# FM33A0XXEV register map
File version: 1.0
CPU: SC000, little endian, no MPU, no FPU, 3 interrupt priority bits
Registers are 32-bit, read-write, reset 0x0 unless marked. A register's access mark holds for its fields unless they carry their own. Offsets are from the block's base; [hi:lo] are bit positions; {n}, {i} and the like mark numbered series.

## ADC — ADC module information
Base 0x4001FA00
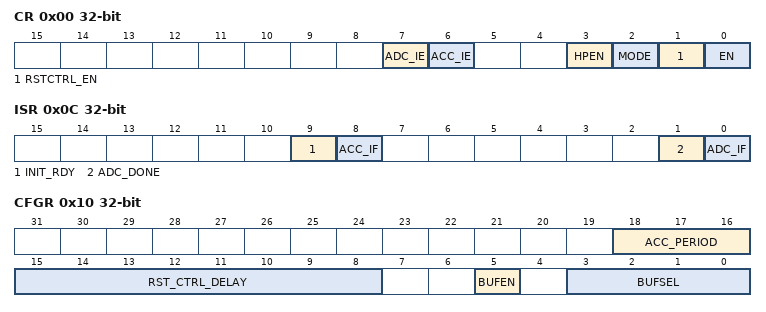
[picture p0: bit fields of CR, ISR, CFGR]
0x00 CR — ADC Control Register
  [7] ADC_IE — ADC_IE field description
  [6] ACC_IE — ACC_IE field description
  [3] HPEN — HPEN field description
  [2] MODE — MODE field description
  [1] RSTCTRL_EN — RSTCTRL_EN field description
  [0] EN — EN field description
0x04 TRIM — ADC Trim Register
  [10:0] ADC_TRIM — ADC_TRIM field description
0x08 DR — ADC Data Register
  [15:0] ADC_DATA ro — ADC_DATA field description
0x0C ISR — ADC Interrupt Status Regsiter
  [9] INIT_RDY ro — INIT_RDY field description
  [8] ACC_IF — ACC_IF field description
  [1] ADC_DONE ro — ADC_DONE field description
  [0] ADC_IF — ADC_IF field description
0x10 CFGR — ADC Config Register
  [18:16] ACC_PERIOD — ACC_PERIOD field description
  [15:8] RST_CTRL_DELAY — RST_CTRL_DELAY field description
  [5] BUFEN — BUFEN field description
  [3:0] BUFSEL — BUFSEL field description

## CIC — CIC module information
Base 0x40015C00
0x00 DR — CIC Output Data Register
  [23:0] ADC_CIC_DATA ro — ADC_CIC_DATA field description
0x04 OS — CIC Output Offset Register
  [23:0] ADC_CIC_OS — ADC_CIC_OS field description
0x08 USDR — CIC Unsigned Data Register
  [23:0] ADC_CIC_USDR ro — ADC_CIC_USDR field description
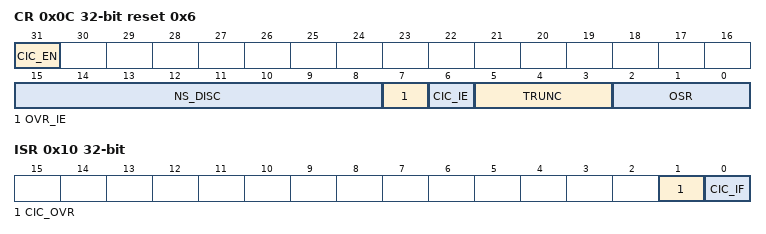
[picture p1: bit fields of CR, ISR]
0x0C CR reset 0x6 — CIC Control Register
  [31] CIC_EN — CIC_EN field description
  [15:8] NS_DISC — NS_DISC field description
  [7] OVR_IE — OVR_IE field description
  [6] CIC_IE — CIC_IE field description
  [5:3] TRUNC — TRUNC field description
  [2:0] OSR — OSR field description
0x10 ISR — CIC Interrupt Status Register
  [1] CIC_OVR — CIC_OVR field description
  [0] CIC_IF — CIC_IF field description

## GPIOA — GPIOA module information
Base 0x40000C00
0x00 INEN — GPIOA Input Enable Register
  [15:0] PxINEN — PxINEN field description
0x04 PUEN — GPIOA Pull-Up Enable Register
  [15:0] PxPUEN — PxPUEN field description
0x08 ODEN — GPIOA Open-Drain Enable Register
  [15:0] PxODEN — PxODEN field description
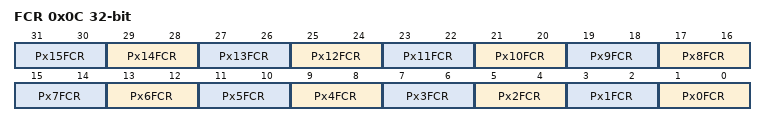
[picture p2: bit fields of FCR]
0x0C FCR — GPIOA Function Control Register
  [2n+1:2n] Px{n}FCR (n=0..15) — Px{n}FCR field description
0x10 DO — GPIOA Data Output Register
  [15:0] PxDO — PxDO field description
0x14 DSET — GPIOA Data Set Register
  [15:0] PxSET wo — PxSET field description
0x18 DRST — GPIOA Data Reset Register
  [15:0] PxRESET wo — PxRESET field description
0x1C DIN — GPIOA Data Input Register
  [15:0] PxDIN ro — PxDIN field description
0x20 DFS — GPIOA Digital Function Select
  [15:0] PxDFS — PxDFS field description
0x28 ANEN — GPIOAAnalog channel Enable Register
  [15:0] PxANEN — PxANEN field description

## GPIOB — GPIOB module information
Base 0x40000C40
Registers as GPIOA (with GPIOA read as GPIOB); these are added or differ:
0x08 ODEN — GPIOB Opeb-Drain Enable Register
  [15:0] PxODEN — PxODEN field description
0x1C DIN — GPIOBData Input Register
  [15:0] PxDIN ro — PxDIN field description
0x28 ANEN — GPIOB Analog channel Enable Register
  [15:0] PxANEN — PxANEN field description

## GPIOC — GPIOC module information
Base 0x40000C80
Registers as GPIOB (with GPIOB read as GPIOC); these are added or differ:
0x1C DIN — GPIOC Data Input Register
  [15:0] PxDIN ro — PxDIN field description

## GPIOD — GPIOD module information
Base 0x40000CC0
Registers as GPIOC (with GPIOC read as GPIOD).

## GPIOE — GPIOE module information
Base 0x40000D00
Registers as GPIOC (with GPIOC read as GPIOE).

## GPIOF — GPIOF module information
Base 0x40000D40
Registers as GPIOC (with GPIOC read as GPIOF).

## GPIOG — GPIOG module information
Base 0x40000D80
Registers as GPIOC (with GPIOC read as GPIOG).

## GPIO — GPIO module information
Base 0x40000DC0
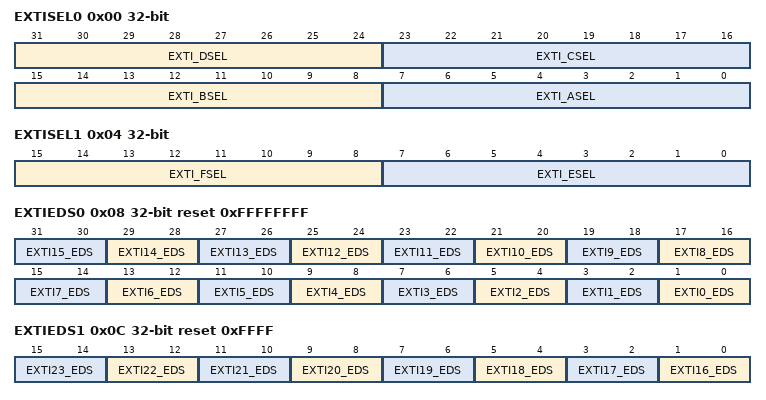
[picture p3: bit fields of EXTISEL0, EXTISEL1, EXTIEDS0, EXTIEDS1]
0x00 EXTISEL0 — External Interrupt input Select Register0
  [31:24] EXTI_DSEL — EXTI_DSEL field description
  [23:16] EXTI_CSEL — EXTI_CSEL field description
  [15:8] EXTI_BSEL — EXTI_BSEL field description
  [7:0] EXTI_ASEL — EXTI_ASEL field description
0x04 EXTISEL1 — External Interrupt input Select Register1
  [15:8] EXTI_FSEL — EXTI_FSEL field description
  [7:0] EXTI_ESEL — EXTI_ESEL field description
0x08 EXTIEDS0 reset 0xFFFFFFFF — External Interrupt Edge Select and Enable Register0
  [2n+1:2n] EXTI{n}_EDS (n=0..15) — EXTI{n}_EDS field description
0x0C EXTIEDS1 reset 0xFFFF — External Interrupt Edge Select and Enable Register1
  [2n-31:2n-32] EXTI{n}_EDS (n=16..23) — EXTI{n}_EDS field description
0x10 EXTIDF — External Interrupt Digital Filter Register
  [23:0] EXTI_DF — EXTI_DF field description
0x14 EXTIISR — External Interrupt and Status Register
  [23:0] EXTI — EXTI field description
0x18 EXTIDI — External Interrupt Data Input Register
  [23:0] EXTI_DI ro — EXTI_DI field description
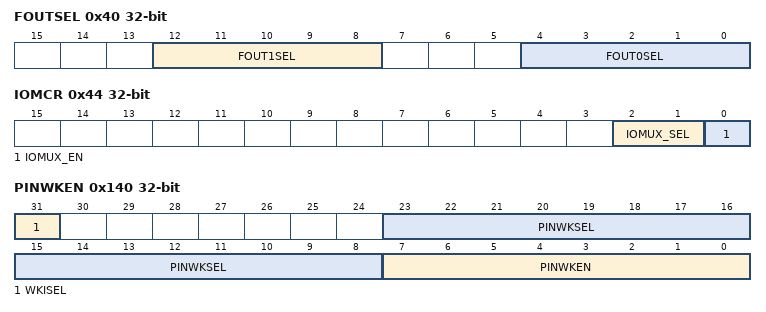
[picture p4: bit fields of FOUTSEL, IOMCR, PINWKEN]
0x40 FOUTSEL — Frequency Output Select Register
  [12:8] FOUT1SEL — FOUT1SEL field description
  [4:0] FOUT0SEL — FOUT0SEL field description
0x44 IOMCR — IO MUX Control Register
  [2:1] IOMUX_SEL — IOMUX_SEL field description
  [0] IOMUX_EN — IOMUX_EN field description
0x140 PINWKEN — Wakeup Enable Register
  [31] WKISEL — WKISEL field description
  [23:8] PINWKSEL — PINWKSEL field description
  [7:0] PINWKEN — PINWKEN field description

## GPIOH — GPIOH module information
Base 0x4001FC00
0x00 INEN — GPIOH Input Enable Register
  [3:0] PHINEN — PHINEN field description
0x04 PUEN — GPIOH Pull-Up Enable Register
  [3:0] PHPUEN — PHPUEN field description
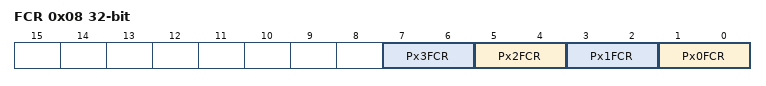
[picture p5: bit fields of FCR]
0x08 FCR — GPIOH Function Control Register
  [2n+1:2n] Px{n}FCR (n=0..3) — Px{n}FCR field description
0x0C DO — GPIOH Data Output Register
  [3:0] PHDO — PHDO field description
0x10 DIN — GPIOH Data Input Register
  [3:0] PHDIN ro — PHDIN field description
